AUTOSAR XML (schema 4-2-2)
package /MCU_FlatView/SwComponentTypes
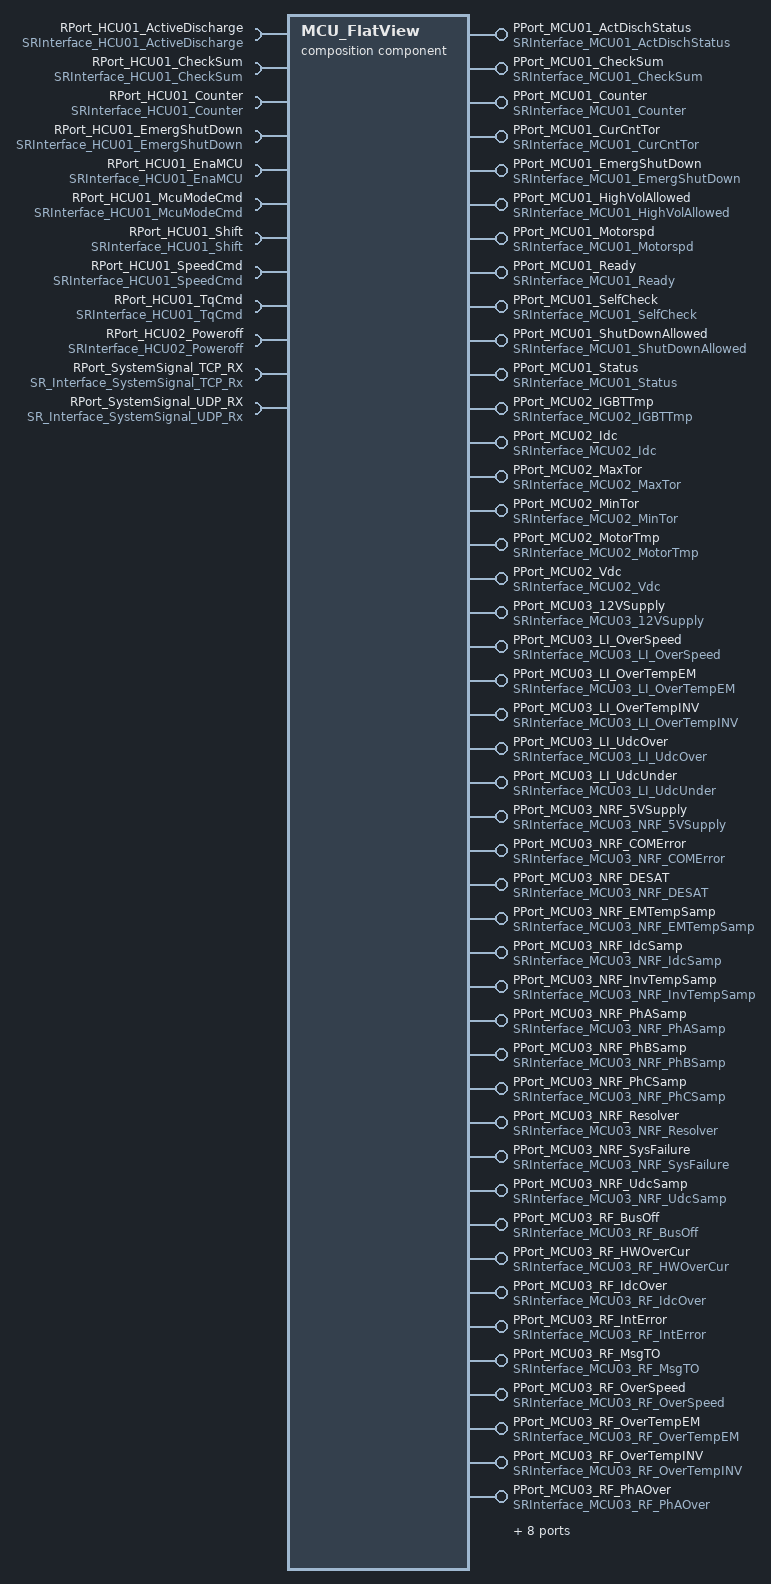
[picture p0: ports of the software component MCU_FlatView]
  composition sw component type MCU_FlatView
    52 x provide port:
      PPort_MCU01_ActDischStatus: provided-interface=SRInterface_MCU01_ActDischStatus
      PPort_MCU01_CheckSum: provided-interface=SRInterface_MCU01_CheckSum
      PPort_MCU01_Counter: provided-interface=SRInterface_MCU01_Counter
      PPort_MCU01_CurCntTor: provided-interface=SRInterface_MCU01_CurCntTor
      PPort_MCU01_EmergShutDown: provided-interface=SRInterface_MCU01_EmergShutDown
      PPort_MCU01_HighVolAllowed: provided-interface=SRInterface_MCU01_HighVolAllowed
      PPort_MCU01_Motorspd: provided-interface=SRInterface_MCU01_Motorspd
      PPort_MCU01_Ready: provided-interface=SRInterface_MCU01_Ready
      PPort_MCU01_SelfCheck: provided-interface=SRInterface_MCU01_SelfCheck
      PPort_MCU01_ShutDownAllowed: provided-interface=SRInterface_MCU01_ShutDownAllowed
      PPort_MCU01_Status: provided-interface=SRInterface_MCU01_Status
      PPort_MCU02_IGBTTmp: provided-interface=SRInterface_MCU02_IGBTTmp
      PPort_MCU02_Idc: provided-interface=SRInterface_MCU02_Idc
      PPort_MCU02_MaxTor: provided-interface=SRInterface_MCU02_MaxTor
      PPort_MCU02_MinTor: provided-interface=SRInterface_MCU02_MinTor
      PPort_MCU02_MotorTmp: provided-interface=SRInterface_MCU02_MotorTmp
      PPort_MCU02_Vdc: provided-interface=SRInterface_MCU02_Vdc
      PPort_MCU03_12VSupply: provided-interface=SRInterface_MCU03_12VSupply
      PPort_MCU03_LI_OverSpeed: provided-interface=SRInterface_MCU03_LI_OverSpeed
      PPort_MCU03_LI_OverTempEM: provided-interface=SRInterface_MCU03_LI_OverTempEM
      PPort_MCU03_LI_OverTempINV: provided-interface=SRInterface_MCU03_LI_OverTempINV
      PPort_MCU03_LI_UdcOver: provided-interface=SRInterface_MCU03_LI_UdcOver
      PPort_MCU03_LI_UdcUnder: provided-interface=SRInterface_MCU03_LI_UdcUnder
      PPort_MCU03_NRF_5VSupply: provided-interface=SRInterface_MCU03_NRF_5VSupply
      PPort_MCU03_NRF_COMError: provided-interface=SRInterface_MCU03_NRF_COMError
      PPort_MCU03_NRF_DESAT: provided-interface=SRInterface_MCU03_NRF_DESAT
      PPort_MCU03_NRF_EMTempSamp: provided-interface=SRInterface_MCU03_NRF_EMTempSamp
      PPort_MCU03_NRF_IdcSamp: provided-interface=SRInterface_MCU03_NRF_IdcSamp
      PPort_MCU03_NRF_InvTempSamp: provided-interface=SRInterface_MCU03_NRF_InvTempSamp
      PPort_MCU03_NRF_PhASamp: provided-interface=SRInterface_MCU03_NRF_PhASamp
      PPort_MCU03_NRF_PhBSamp: provided-interface=SRInterface_MCU03_NRF_PhBSamp
      PPort_MCU03_NRF_PhCSamp: provided-interface=SRInterface_MCU03_NRF_PhCSamp
      PPort_MCU03_NRF_Resolver: provided-interface=SRInterface_MCU03_NRF_Resolver
      PPort_MCU03_NRF_SysFailure: provided-interface=SRInterface_MCU03_NRF_SysFailure
      PPort_MCU03_NRF_UdcSamp: provided-interface=SRInterface_MCU03_NRF_UdcSamp
      PPort_MCU03_RF_BusOff: provided-interface=SRInterface_MCU03_RF_BusOff
      PPort_MCU03_RF_HWOverCur: provided-interface=SRInterface_MCU03_RF_HWOverCur
      PPort_MCU03_RF_IdcOver: provided-interface=SRInterface_MCU03_RF_IdcOver
      PPort_MCU03_RF_IntError: provided-interface=SRInterface_MCU03_RF_IntError
      PPort_MCU03_RF_MsgTO: provided-interface=SRInterface_MCU03_RF_MsgTO
      PPort_MCU03_RF_OverSpeed: provided-interface=SRInterface_MCU03_RF_OverSpeed
      PPort_MCU03_RF_OverTempEM: provided-interface=SRInterface_MCU03_RF_OverTempEM
      PPort_MCU03_RF_OverTempINV: provided-interface=SRInterface_MCU03_RF_OverTempINV
      PPort_MCU03_RF_PhAOver: provided-interface=SRInterface_MCU03_RF_PhAOver
      PPort_MCU03_RF_PhBOver: provided-interface=SRInterface_MCU03_RF_PhBOver
      PPort_MCU03_RF_PhCOver: provided-interface=SRInterface_MCU03_RF_PhCOver
      PPort_MCU03_RF_PhaseImp: provided-interface=SRInterface_MCU03_RF_PhaseImp
      PPort_MCU03_RF_ToqError: provided-interface=SRInterface_MCU03_RF_ToqError
      PPort_MCU03_RF_UDCUnder: provided-interface=SRInterface_MCU03_RF_UDCUnder
      PPort_MCU03_RF_UdcOver: provided-interface=SRInterface_MCU03_RF_UdcOver
      PPort_SystemSignal_TCP_TX: provided-interface=SR_Interface_SystemSignal_TCP_Tx
      PPort_SystemSignal_UDP_TX: provided-interface=SR_Interface_SystemSignal_UDP_Tx
    12 x require port:
      RPort_HCU01_ActiveDischarge: nonqueued-receiver-com-spec{data-element=HCU01_ActiveDischarge, alive-timeout=0.5}, required-interface=SRInterface_HCU01_ActiveDischarge
      RPort_HCU01_CheckSum: nonqueued-receiver-com-spec{data-element=HCU01_CheckSum, alive-timeout=0.5}, required-interface=SRInterface_HCU01_CheckSum
      RPort_HCU01_Counter: nonqueued-receiver-com-spec{data-element=HCU01_Counter, alive-timeout=0.5}, required-interface=SRInterface_HCU01_Counter
      RPort_HCU01_EmergShutDown: nonqueued-receiver-com-spec{data-element=HCU01_EmergShutDown, alive-timeout=0.5}, required-interface=SRInterface_HCU01_EmergShutDown
      RPort_HCU01_EnaMCU: nonqueued-receiver-com-spec{data-element=HCU01_EnaMCU, alive-timeout=0.5}, required-interface=SRInterface_HCU01_EnaMCU
      RPort_HCU01_McuModeCmd: nonqueued-receiver-com-spec{data-element=HCU01_McuModeCmd, alive-timeout=0.5}, required-interface=SRInterface_HCU01_McuModeCmd
      RPort_HCU01_Shift: nonqueued-receiver-com-spec{data-element=HCU01_Shift, alive-timeout=0.5}, required-interface=SRInterface_HCU01_Shift
      RPort_HCU01_SpeedCmd: nonqueued-receiver-com-spec{data-element=HCU01_SpeedCmd, alive-timeout=0.5}, required-interface=SRInterface_HCU01_SpeedCmd
      RPort_HCU01_TqCmd: nonqueued-receiver-com-spec{data-element=HCU01_TqCmd, alive-timeout=0.5}, required-interface=SRInterface_HCU01_TqCmd
      RPort_HCU02_Poweroff: nonqueued-receiver-com-spec{data-element=HCU02_Poweroff, alive-timeout=0.5}, required-interface=SRInterface_HCU02_Poweroff
      RPort_SystemSignal_TCP_RX: required-interface=SR_Interface_SystemSignal_TCP_Rx
      RPort_SystemSignal_UDP_RX: required-interface=SR_Interface_SystemSignal_UDP_Rx
    42 x component:
      CPT_ASW_COM: type=ASW_COM
      CPT_ASW_CORE{0..5}: type=ASW_CORE{0..5}
      CPT_ASW_DCM: type=ASW_DCM
      CPT_ASW_DEM: type=ASW_DEM
      CPT_ASW_ETH: type=ASW_ETH
      CPT_ASW_NM: type=ASW_NM
      CPT_ASW_NVM: type=ASW_NVM
      CPT_ASW_StbM: type=ASW_StbM
      CPT_ASW_WDG: type=ASW_WDG
      CPT_BswM: type=BswM
      CPT_CDD_CORE{0..5}: type=CDD_CORE{0..5}
      CPT_ComM: type=ComM
      CPT_Dcm: type=Dcm
      CPT_Dem: type=Dem
      CPT_Det: type=Det
      CPT_DoIP: type=DoIP
      CPT_EcuM: type=EcuM
      CPT_IoHwAb_ADC: type=IoHwAb_ADC
      CPT_IoHwAb_DIO: type=IoHwAb_DIO
      CPT_IoHwAb_DIO_Test: type=IoHwAb_DIO_Test
      CPT_IoHwAb_ICU: type=IoHwAb_ICU
      CPT_IoHwAb_PWM: type=IoHwAb_PWM
      CPT_NvM: type=NvM
      CPT_SensorActuator_ADC: type=SensorActuator_ADC
      CPT_SensorActuator_DIO: type=SensorActuator_DIO
      CPT_SensorActuator_DIO_Test: type=SensorActuator_DIO_Test
      CPT_SensorActuator_ICU: type=SensorActuator_ICU
      CPT_SensorActuator_PWM: type=SensorActuator_PWM
      CPT_StbM: type=StbM
      CPT_WdgM: type=WdgM
      CPT_XCP: type=ASW_XCP
      CPT_rba_DiagLib: type=rba_DiagLib
    connect CPT_ASW_CORE0.PPort_SwcModeRequest -> CPT_BswM.RP_BswMArbitration_BswMSwcModeRequest
    connect CPT_ASW_DCM.PPortPrototype_NRC22 -> CPT_Dcm.Rp_ModeDeclarationGroup_NRC22
    connect CPT_ASW_DCM.PPortPrototype_NRC72 -> CPT_Dcm.Rp_ModeDeclarationGroup_NRC72
    connect CPT_ASW_DCM.PPort_IOControl_EngineTemperature -> CPT_Dcm.DataServices_EngineTemperature
    connect CPT_ASW_DCM.PPort_IOControl_PowerMode -> CPT_Dcm.DataServices_PowerMode
    connect CPT_ASW_DCM.PPort_IOControl_VacuumPumpPressure -> CPT_Dcm.DataServices_VacuumPumpPres
    connect CPT_ASW_DCM.PPort_Routine_CheckMemoryCRC -> CPT_Dcm.RoutineServices_DcmDspRoutine_CheckMemoryCRC
    connect CPT_ASW_DCM.PPort_Routine_DriveVacuumPump -> CPT_Dcm.RoutineServices_DcmDspRoutine_DriveVacuumPump
    connect CPT_ASW_DCM.P_DataServices_DcmDspData_ECU_NCF_Reference_Number -> CPT_Dcm.R_DataServices_ECU_NCF_Ref_Num
    connect CPT_ASW_DCM.P_DataServices_DcmDspData_ECU_Serial_Number -> CPT_Dcm.R_DataServices_ECU_Serial_Number
    connect CPT_ASW_DCM.P_DataServices_DcmDspData_HaRef -> CPT_Dcm.R_DataServices_ECU_HW_Ref_Num
    connect CPT_ASW_DCM.P_DataServices_DcmDspData_SwRef -> CPT_Dcm.R_DataServices_ECU_SW_Ref_Num
    connect CPT_ASW_DCM.P_DataServices_DcmDspData_SystemFaultRank_Read -> CPT_Dcm.R_DataServices_SystemFaultRank
    connect CPT_ASW_DCM.P_DataServices_DcmDspData_VIN -> CPT_Dcm.R_DataServices_DcmDspData_VIN
    connect CPT_ASW_DCM.P_DataServices_DcmDspData_VehicleSpeed_Read -> CPT_Dcm.R_DataServices_VehicleSpeed
    connect CPT_ASW_DEM.DataServices_CS_ExtendedDataRecord_Aged_counter -> CPT_Dem.DataServices_CS_ExtendedDataRecord_Aged_counter
    connect CPT_ASW_DEM.DataServices_CS_ExtendedDataRecord_Fault_pending_counter -> CPT_Dem.DataServices_CS_ExtendedDataRecord_Fault_pending_counter
    connect CPT_ASW_DEM.DataServices_DemDataElementClass_Day -> CPT_Dem.DataServices_DemDataElementClass_Day
    connect CPT_ASW_DEM.DataServices_DemDataElementClass_Hour -> CPT_Dem.DataServices_DemDataElementClass_Hour
    connect CPT_ASW_DEM.DataServices_DemDataElementClass_Minute -> CPT_Dem.DataServices_DemDataElementClass_Minute
    connect CPT_ASW_DEM.DataServices_DemDataElementClass_Month -> CPT_Dem.DataServices_DemDataElementClass_Month
    connect CPT_ASW_DEM.DataServices_DemDataElementClass_OdometerReading -> CPT_Dem.DataServices_DemDataElementClass_OdometerReading
    connect CPT_ASW_DEM.DataServices_DemDataElementClass_PowerMode -> CPT_Dem.DataServices_DemDataElementClass_PowerMode
    connect CPT_ASW_DEM.DataServices_DemDataElementClass_SupplyVoltage -> CPT_Dem.DataServices_DemDataElementClass_SupplyVoltage
    connect CPT_ASW_DEM.DataServices_DemDataElementClass_Year -> CPT_Dem.DataServices_DemDataElementClass_Year
    connect CPT_ASW_DEM.PPort_CBStatusComp_DemComponent_0D{01..05} -> CPT_Dem.CBStatusComp_DemComponent_0D{01..05}
    connect CPT_ASW_DEM.PPort_CBStatusComp_DemComponent_0D06_Comb0 -> CPT_Dem.CBStatusComp_DemComponent_0D06_Comb0
    connect CPT_ASW_DEM.PPort_CBStatusComp_DemComponent_0D06_Comb1 -> CPT_Dem.CBStatusComp_DemComponent_0D06_Comb1
    connect CPT_ASW_ETH.PPort_CallbackGetPowerMode -> CPT_DoIP.CBGetPowerMode
    connect CPT_ASW_ETH.PPort_DoIPActivationLineSwitchNotification -> CPT_DoIP.DoIPActivationLineSwitchNotification
    connect CPT_ASW_NM.PP_BswMArbitration_BswM_MRP_Network -> CPT_BswM.RP_BswMArbitration_BswM_MRP_SWC_Network
    connect CPT_ASW_NM.PP_BswMArbitration_BswM_MRP_NmState -> CPT_BswM.RP_BswMArbitration_BswM_MRP_SWC_Network
    connect CPT_CDD_CORE0.PPort_CPUUtilizationCore0 -> CPT_ASW_CORE0.RPort_CPUUtilizationCore0
    connect CPT_CDD_CORE0.PPort_GetMaxUserStackUtilization -> CPT_ASW_CORE0.RPort_GetMaxUserStackUtilization
    connect CPT_CDD_CORE1.PPort_CPUUtilizationCore1 -> CPT_ASW_CORE1.RPort_CPUUtilizationCore1
    connect CPT_CDD_CORE1.PPort_GetMaxUserStackUtilization -> CPT_ASW_CORE1.RPort_GetMaxUserStackUtilization
    connect CPT_CDD_CORE2.PPort_CPUUtilizationCore2 -> CPT_ASW_CORE2.RPort_CPUUtilizationCore2
    connect CPT_CDD_CORE2.PPort_GetMaxUserStackUtilization -> CPT_ASW_CORE2.RPort_GetMaxUserStackUtilization
    connect CPT_CDD_CORE3.PPort_CPUUtilizationCore3 -> CPT_ASW_CORE3.RPort_CPUUtilizationCore3
    connect CPT_CDD_CORE3.PPort_GetMaxUserStackUtilization -> CPT_ASW_CORE3.RPort_GetMaxUserStackUtilization
    connect CPT_CDD_CORE4.PPort_CPUUtilizationCore4 -> CPT_ASW_CORE4.RPort_CPUUtilizationCore4
    connect CPT_CDD_CORE4.PPort_GetMaxUserStackUtilization -> CPT_ASW_CORE4.RPort_GetMaxUserStackUtilization
    connect CPT_CDD_CORE5.PPort_CPUUtilizationCore5 -> CPT_ASW_CORE5.RPort_CPUUtilizationCore5
    connect CPT_CDD_CORE5.PPort_GetMaxUserStackUtilization -> CPT_ASW_CORE5.RPort_GetMaxUserStackUtilization
    connect CPT_ComM.UR_ComMUser_Can_Network_Channel -> CPT_ASW_NM.RP_ComM_UserRequest_CAN0
    connect CPT_ComM.modeLimitation -> CPT_ASW_NM.RPort_EcuModeLimitation
    connect CPT_Dcm.DCMServices -> CPT_ASW_DCM.RPort_DCMServices
    connect CPT_Dcm.P_DataServices_DcmDspData_VIN -> CPT_ASW_DCM.R_DataServices_DcmDspData_VIN
    connect CPT_Dcm.P_DataServices_ECU_Serial_Number -> CPT_ASW_DCM.R_DataServices_DcmDspData_ECU_Serial_Number
    connect CPT_Dcm.P_DataServices_SystemFaultRank -> CPT_ASW_DCM.RPort_DataServices_DcmDspData_SystemFaultRank_Write
    connect CPT_Dcm.P_DataServices_VehicleSpeed -> CPT_ASW_DCM.RPort_DataServices_DcmDspData_VehicleSpeed_Write
    connect CPT_Dem.Event_DemEventParameter_0D01_SWC -> CPT_ASW_DEM.Event_DemEventParameter_0D01
    connect CPT_Dem.Event_DemEventParameter_0D02_SWC -> CPT_ASW_DEM.Event_DemEventParameter_0D02
    connect CPT_Dem.Event_DemEventParameter_0D06_Comb0 -> CPT_ASW_DEM.Event_DemEventParameter_0D06_Comb0
    connect CPT_Dem.Event_DemEventParameter_0D06_Comb1 -> CPT_ASW_DEM.Event_DemEventParameter_0D06_Comb1
    connect CPT_Dem.OpCycle_DemOperationCycle_Power -> CPT_ASW_DEM.RPort_OpCycle_DemOperationCycle_Power
    connect CPT_IoHwAb_ADC.PPortADC_SAR0_10 -> CPT_SensorActuator_ADC.RPort_ADC_Get_SAR0_10
    connect CPT_IoHwAb_ADC.PPortADC_SAR0_31 -> CPT_SensorActuator_ADC.RPort_ADC_Get_SAR0_31
    connect CPT_IoHwAb_ADC.PPortADC_SAR1_12 -> CPT_SensorActuator_ADC.RPort_ADC_Get_SAR1_12
    connect CPT_IoHwAb_DIO.PPort_DIO_Get_0 -> CPT_SensorActuator_DIO.RPort_DIO_Get_0
    connect CPT_IoHwAb_DIO.PPort_DIO_Get_1 -> CPT_SensorActuator_DIO.RPort_DIO_Get_1
    connect CPT_IoHwAb_DIO.PPort_DIO_Set_0 -> CPT_SensorActuator_DIO.RPort_DIO_Set_0
    connect CPT_IoHwAb_DIO.PPort_DIO_Set_1 -> CPT_SensorActuator_DIO.RPort_DIO_Set_1
    connect CPT_IoHwAb_DIO_Test.PPort_Dio_SetChannel -> CPT_SensorActuator_DIO_Test.RPort_Dio_Set
    connect CPT_IoHwAb_ICU.PPort_ICU_PZ_1 -> CPT_SensorActuator_ICU.RPort_ICU_PZ_1
    connect CPT_IoHwAb_PWM.PPort_PWM_PG_9 -> CPT_SensorActuator_PWM.RPort_PWM_PG_9
    connect CPT_NvM.NvM_NativeBlock_2 -> CPT_ASW_NVM.RPort_ASW_NVM_BlockNative_1024_1
    connect CPT_NvM.NvM_NativeBlock_3 -> CPT_ASW_NVM.RPort_ASW_NVM_BlockNative_1024_2
    connect CPT_StbM.GlobalTime_Master_StbMSynchronizedTimeBase_Eth -> CPT_ASW_StbM.RP_GlobalTime_Master_StbMSynchronizedTimeBase_Eth
    connect CPT_WdgM.globalMode -> CPT_ASW_WDG.RPort_WdgM_GlobalMode
    connect CPT_WdgM.localSupervision_WdgMSupervisedEntity_Alive_Supervision_Entity1_WdgMCheckpoint_Alive_Supervision_Entity1 -> CPT_ASW_WDG.RPort_Alive_Supervision_Entity1
    connect CPT_WdgM.localSupervision_WdgMSupervisedEntity_Deadline_Supervision_Entity1_WdgMCheckpoint_Deadline_Supervision_Entity1 -> CPT_ASW_WDG.RPort_Deadline_Supervision_Entity1
    connect CPT_WdgM.localSupervision_WdgMSupervisedEntity_Deadline_Supervision_Entity1_WdgMCheckpoint_Deadline_Supervision_Entity2 -> CPT_ASW_WDG.RPort_Deadline_Supervision_Entity2
    delegate CPT_ASW_COM.PPort_MCU01_ActDischStatus <-> outer port PPort_MCU01_ActDischStatus
    delegate CPT_ASW_COM.PPort_MCU01_CheckSum <-> outer port PPort_MCU01_CheckSum
    delegate CPT_ASW_COM.PPort_MCU01_Counter <-> outer port PPort_MCU01_Counter
    delegate CPT_ASW_COM.PPort_MCU01_CurCntTor <-> outer port PPort_MCU01_CurCntTor
    delegate CPT_ASW_COM.PPort_MCU01_EmergShutDown <-> outer port PPort_MCU01_EmergShutDown
    delegate CPT_ASW_COM.PPort_MCU01_HighVolAllowed <-> outer port PPort_MCU01_HighVolAllowed
    delegate CPT_ASW_COM.PPort_MCU01_Motorspd <-> outer port PPort_MCU01_Motorspd
    delegate CPT_ASW_COM.PPort_MCU01_Ready <-> outer port PPort_MCU01_Ready
    delegate CPT_ASW_COM.PPort_MCU01_SelfCheck <-> outer port PPort_MCU01_SelfCheck
    delegate CPT_ASW_COM.PPort_MCU01_ShutDownAllowed <-> outer port PPort_MCU01_ShutDownAllowed
    delegate CPT_ASW_COM.PPort_MCU01_Status <-> outer port PPort_MCU01_Status
    delegate CPT_ASW_COM.PPort_MCU02_IGBTTmp <-> outer port PPort_MCU02_IGBTTmp
    delegate CPT_ASW_COM.PPort_MCU02_Idc <-> outer port PPort_MCU02_Idc
    delegate CPT_ASW_COM.PPort_MCU02_MaxTor <-> outer port PPort_MCU02_MaxTor
    delegate CPT_ASW_COM.PPort_MCU02_MinTor <-> outer port PPort_MCU02_MinTor
    delegate CPT_ASW_COM.PPort_MCU02_MotorTmp <-> outer port PPort_MCU02_MotorTmp
    delegate CPT_ASW_COM.PPort_MCU02_Vdc <-> outer port PPort_MCU02_Vdc
    delegate CPT_ASW_COM.PPort_MCU03_12VSupply <-> outer port PPort_MCU03_12VSupply
    delegate CPT_ASW_COM.PPort_MCU03_LI_OverSpeed <-> outer port PPort_MCU03_LI_OverSpeed
    delegate CPT_ASW_COM.PPort_MCU03_LI_OverTempEM <-> outer port PPort_MCU03_LI_OverTempEM
    delegate CPT_ASW_COM.PPort_MCU03_LI_OverTempINV <-> outer port PPort_MCU03_LI_OverTempINV
    delegate CPT_ASW_COM.PPort_MCU03_LI_UdcOver <-> outer port PPort_MCU03_LI_UdcOver
    delegate CPT_ASW_COM.PPort_MCU03_LI_UdcUnder <-> outer port PPort_MCU03_LI_UdcUnder
    delegate CPT_ASW_COM.PPort_MCU03_NRF_5VSupply <-> outer port PPort_MCU03_NRF_5VSupply
    delegate CPT_ASW_COM.PPort_MCU03_NRF_COMError <-> outer port PPort_MCU03_NRF_COMError
    delegate CPT_ASW_COM.PPort_MCU03_NRF_DESAT <-> outer port PPort_MCU03_NRF_DESAT
    delegate CPT_ASW_COM.PPort_MCU03_NRF_EMTempSamp <-> outer port PPort_MCU03_NRF_EMTempSamp
    delegate CPT_ASW_COM.PPort_MCU03_NRF_IdcSamp <-> outer port PPort_MCU03_NRF_IdcSamp
    delegate CPT_ASW_COM.PPort_MCU03_NRF_InvTempSamp <-> outer port PPort_MCU03_NRF_InvTempSamp
    delegate CPT_ASW_COM.PPort_MCU03_NRF_PhASamp <-> outer port PPort_MCU03_NRF_PhASamp
    delegate CPT_ASW_COM.PPort_MCU03_NRF_PhBSamp <-> outer port PPort_MCU03_NRF_PhBSamp
    delegate CPT_ASW_COM.PPort_MCU03_NRF_PhCSamp <-> outer port PPort_MCU03_NRF_PhCSamp
    delegate CPT_ASW_COM.PPort_MCU03_NRF_Resolver <-> outer port PPort_MCU03_NRF_Resolver
    delegate CPT_ASW_COM.PPort_MCU03_NRF_SysFailure <-> outer port PPort_MCU03_NRF_SysFailure
    delegate CPT_ASW_COM.PPort_MCU03_NRF_UdcSamp <-> outer port PPort_MCU03_NRF_UdcSamp
    delegate CPT_ASW_COM.PPort_MCU03_RF_BusOff <-> outer port PPort_MCU03_RF_BusOff
    delegate CPT_ASW_COM.PPort_MCU03_RF_HWOverCur <-> outer port PPort_MCU03_RF_HWOverCur
    delegate CPT_ASW_COM.PPort_MCU03_RF_IdcOver <-> outer port PPort_MCU03_RF_IdcOver
    delegate CPT_ASW_COM.PPort_MCU03_RF_IntError <-> outer port PPort_MCU03_RF_IntError
    delegate CPT_ASW_COM.PPort_MCU03_RF_MsgTO <-> outer port PPort_MCU03_RF_MsgTO
    delegate CPT_ASW_COM.PPort_MCU03_RF_OverSpeed <-> outer port PPort_MCU03_RF_OverSpeed
    delegate CPT_ASW_COM.PPort_MCU03_RF_OverTempEM <-> outer port PPort_MCU03_RF_OverTempEM
    delegate CPT_ASW_COM.PPort_MCU03_RF_OverTempINV <-> outer port PPort_MCU03_RF_OverTempINV
    delegate CPT_ASW_COM.PPort_MCU03_RF_PhAOver <-> outer port PPort_MCU03_RF_PhAOver
    delegate CPT_ASW_COM.PPort_MCU03_RF_PhBOver <-> outer port PPort_MCU03_RF_PhBOver
    delegate CPT_ASW_COM.PPort_MCU03_RF_PhCOver <-> outer port PPort_MCU03_RF_PhCOver
    delegate CPT_ASW_COM.PPort_MCU03_RF_PhaseImp <-> outer port PPort_MCU03_RF_PhaseImp
    delegate CPT_ASW_COM.PPort_MCU03_RF_ToqError <-> outer port PPort_MCU03_RF_ToqError
    delegate CPT_ASW_COM.PPort_MCU03_RF_UDCUnder <-> outer port PPort_MCU03_RF_UDCUnder
    delegate CPT_ASW_COM.PPort_MCU03_RF_UdcOver <-> outer port PPort_MCU03_RF_UdcOver
    delegate CPT_ASW_ETH.PPort_SystemSignal_TCP_TX <-> outer port PPort_SystemSignal_TCP_TX
    delegate CPT_ASW_ETH.PPort_SystemSignal_UDP_TX <-> outer port PPort_SystemSignal_UDP_TX
    delegate CPT_ASW_COM.RPort_HCU01_ActiveDischarge <-> outer port RPort_HCU01_ActiveDischarge
    delegate CPT_ASW_COM.RPort_HCU01_CheckSum <-> outer port RPort_HCU01_CheckSum
    delegate CPT_ASW_COM.RPort_HCU01_Counter <-> outer port RPort_HCU01_Counter
    delegate CPT_ASW_COM.RPort_HCU01_EmergShutDown <-> outer port RPort_HCU01_EmergShutDown
    delegate CPT_ASW_COM.RPort_HCU01_EnaMCU <-> outer port RPort_HCU01_EnaMCU
    delegate CPT_ASW_COM.RPort_HCU01_McuModeCmd <-> outer port RPort_HCU01_McuModeCmd
    delegate CPT_ASW_COM.RPort_HCU01_Shift <-> outer port RPort_HCU01_Shift
    delegate CPT_ASW_COM.RPort_HCU01_SpeedCmd <-> outer port RPort_HCU01_SpeedCmd
    delegate CPT_ASW_COM.RPort_HCU01_TqCmd <-> outer port RPort_HCU01_TqCmd
    delegate CPT_ASW_COM.RPort_HCU02_Poweroff <-> outer port RPort_HCU02_Poweroff
    delegate CPT_ASW_ETH.RPort_SystemSignal_TCP_RX <-> outer port RPort_SystemSignal_TCP_RX
    delegate CPT_ASW_ETH.RPort_SystemSignal_UDP_RX <-> outer port RPort_SystemSignal_UDP_RX
